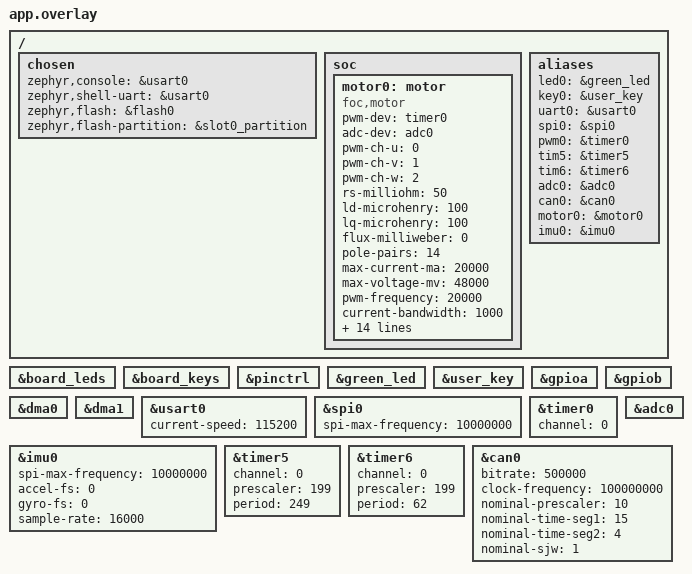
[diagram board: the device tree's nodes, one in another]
/* Application device selection and operating parameters. */
&board_leds { status = "okay"; };
&board_keys { status = "okay"; };
&pinctrl { status = "okay"; };

/ {
    chosen {
        zephyr,console = &usart0;
        zephyr,shell-uart = &usart0;
        zephyr,flash = &flash0;
        zephyr,flash-partition = &slot0_partition;
    };
    soc {
        motor0: motor {
            compatible = "foc,motor";
            status = "okay";
            pwm-dev = <&timer0>;
            adc-dev = <&adc0>;
            pwm-ch-u = <0>;
            pwm-ch-v = <1>;
            pwm-ch-w = <2>;
            rs-milliohm = <50>;
            ld-microhenry = <100>;
            lq-microhenry = <100>;
            flux-milliweber = <0>;
            pole-pairs = <14>;
            max-current-ma = <20000>;
            max-voltage-mv = <48000>;
            pwm-frequency = <20000>;
            current-bandwidth = <1000>;
            timer-clock-hz = <200000000>;
            pwm-prescaler = <0>;
            dead-time-ns = <500>;
            adc-resolution-bits = <12>;
            current-u-channel = <0>;
            current-w-channel = <1>;
            vbus-channel = <2>;
            adc-trigger-source = <0>;
            adc-reference-mv = <3300>;
            current-zero-code = <2048>;
            current-sense-uv-per-amp = <100000>;
            vbus-divider-milli = <20000>;
            sensor-mode = <0>;
            /* Product LESO/PID loops publish torque; disable the core speed PI. */
            control-mode = <0>;
        };
    };
    aliases {
        led0 = &green_led;
        key0 = &user_key;
        uart0 = &usart0;
        spi0 = &spi0;
        pwm0 = &timer0;
        tim5 = &timer5;
        tim6 = &timer6;
        adc0 = &adc0;
        can0 = &can0;
        motor0 = &motor0;
        imu0 = &imu0;
    };
};

&green_led {
    status = "okay";
};

&user_key {
    status = "okay";
};

&gpioa {
    status = "okay";
};

&gpiob {
    status = "okay";
};

&dma0 {
    status = "okay";
};

&dma1 {
    status = "okay";
};

&usart0 {
    status = "okay";
    current-speed = <115200>;
};

&spi0 {
    status = "okay";
    spi-max-frequency = <10000000>;
};

&imu0 {
    status = "okay";
    spi-max-frequency = <10000000>;
    accel-fs = <0>;
    gyro-fs = <0>;
    sample-rate = <16000>;
};

&timer0 {
    status = "okay";
    channel = <0>;
};

&timer5 {
    status = "okay";
    channel = <0>;
    prescaler = <199>;   /* 200MHz / 200 = 1MHz */
    period = <249>;      /* 1MHz / 250 = 4kHz */
};

&timer6 {
    status = "okay";
    channel = <0>;
    prescaler = <199>;   /* 200MHz / 200 = 1MHz */
    period = <62>;       /* 1MHz / 63 ≈ 15.87kHz ≈ 16kHz */
};

&adc0 {
    status = "okay";
};

&can0 {
    status = "okay";
    bitrate = <500000>;
    clock-frequency = <100000000>;
    nominal-prescaler = <10>;
    nominal-time-seg1 = <15>;
    nominal-time-seg2 = <4>;
    nominal-sjw = <1>;
};
